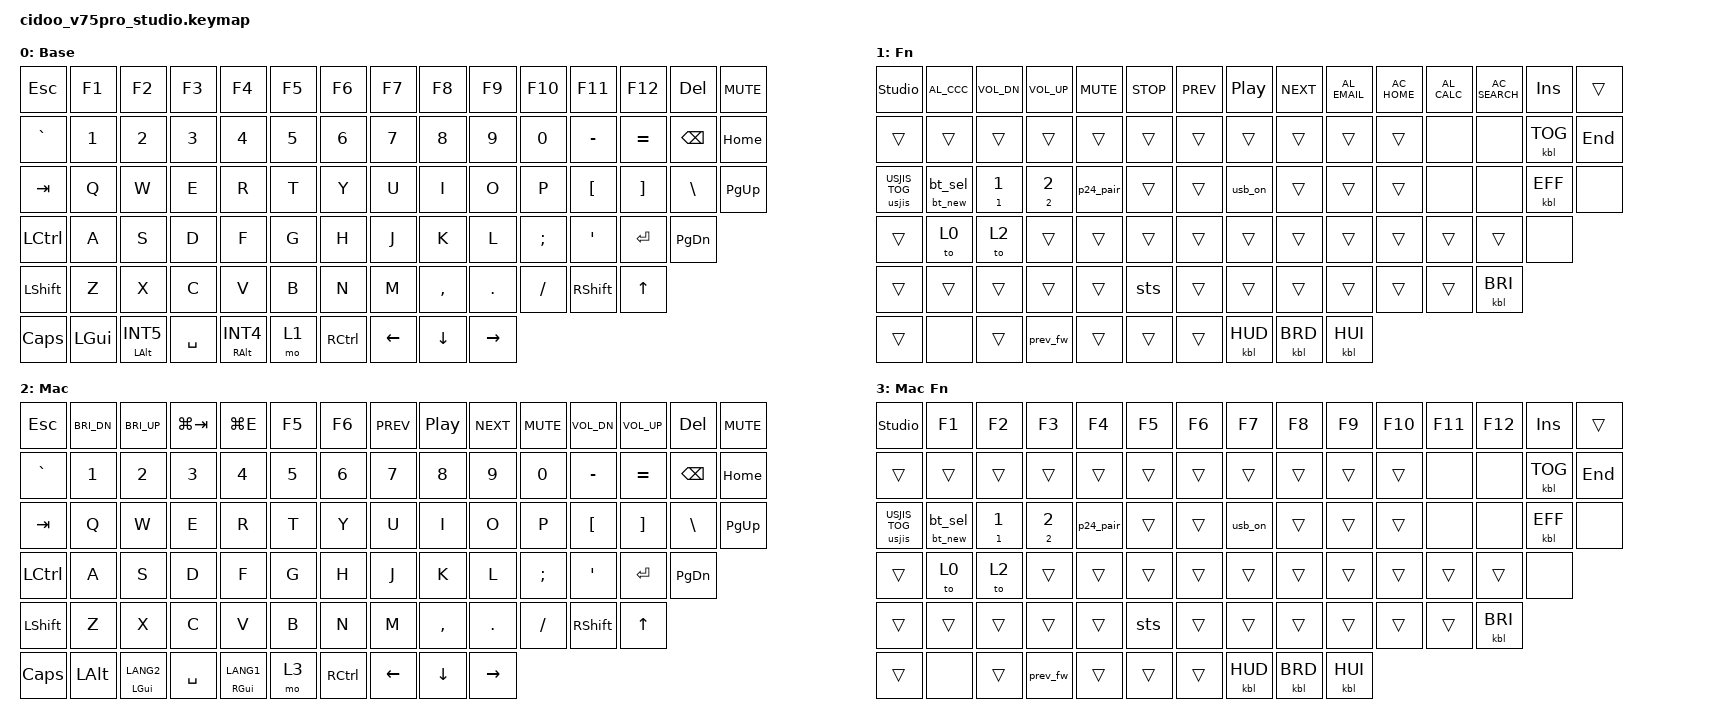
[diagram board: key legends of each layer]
/*
 * SPDX-License-Identifier: GPL-3.0-or-later
 */

/*
 * CIDOO V75 Pro keymap for the own BLE stack (TLSR_BLE), the 2.4G link (TLSR_P24),
 * the backlight (LED_DRIVER_SPI) and ZMK Studio over a USB serial port, with
 * the original firmware's Windows and Mac modes as layers: Base and Fn for Windows, Mac and Mac Fn
 * for the Mac. Fn + S (the original firmware's MAC MODE) turns the Mac layer on, Fn + A (WIN MODE)
 * off, and the layer's state is kept over a boot (TLSR_KEPT_LAYER). The Mac layers are
 * the original firmware's Mac mode as seen on it: F1/F2 the display brightness, F3/F4 Cmd+Tab and
 * Cmd+E, F7-F12 the media keys, Alt and Cmd swapped, the right Alt a Cmd; with Fn the F
 * row gives F1-F12. Fn + Esc unlocks Studio.
 * US-JIS (src/usjis.c): Fn + Tab toggles it (&usjis USJIS_TOG; Studio also offers On and
 * Off), only the Win layers substitute (CONFIG_ZMK_USJIS_LAYER_EXCLUDE_MASK), and a change
 * blinks the LEDs left of the knob green (on) or red (off). Defaults any key can be given
 * back in Studio: Caps Lock and the left Ctrl swapped, and the keys beside Space hold their
 * modifier and tap the IME keys (&ime_ht, hold-preferred, 200 ms): Win Alt / Muhenkan
 * (INT5) and Alt / Henkan (INT4), Mac Cmd / Eisu (LANG2) and Cmd / Kana (LANG1).
 * The backlight keymap is cidoo_v75pro_wireless.keymap: cidoo_v75pro_ble.keymap with the
 * original firmware's backlight keys bound (&kbl): Fn + Backspace toggles, Fn + \ steps the
 * effect, Fn + Up/Down the brightness, Fn + Right/Left the colour, as on the
 * original firmware. The original firmware's speed and saturation keys stay unbound.
 * The BLE keymap is the same as cidoo_v75pro.keymap but for the original firmware's BT channel keys
 * (Fn + Q/W/E): a tap selects ZMK profile 0/1/2, held 3 s it selects it and clears
 * its bond; and the original firmware's 2.4G key (Fn + R): held 3 s in the 2.4G position, it pairs.
 * Generated by gen_v75pro.py from the original keymap's layers 0 (Base) and 1 (Fn).
 * Original knob: left = &kp C_VOL_DN, right = &kp C_VOL_UP, press = 0,14.
 */

#include <behaviors.dtsi>
#include <dt-bindings/zmk/keys.h>
#include <dt-bindings/zmk/bt.h>
#include <dt-bindings/zmk/rgb.h>
#include <dt-bindings/zmk/usjis.h>

/ {
    chosen {
        zmk,studio-rpc-uart = &studio_rpc_usb_uart;
    };
};

/ {
    macros {
        bt_sel: bt_sel {
            compatible = "zmk,behavior-macro-one-param";
            #binding-cells = <1>;
            bindings = <&macro_param_1to2>, <&bt BT_SEL MACRO_PLACEHOLDER>;
        };
        bt_new: bt_new {
            compatible = "zmk,behavior-macro-one-param";
            #binding-cells = <1>;
            bindings = <&macro_param_1to2>, <&bt BT_SEL MACRO_PLACEHOLDER>, <&bt BT_CLR>;
        };
    };

    behaviors {
        /* The original firmware's 2.4G pairing key, Fn + R held 3 s (the 2.4G position only) */
        /* ZMK's RGB commands for the backlight (src/led_driver_spi.c) */
        kbl: backlight {
            compatible = "zmk,behavior-backlight-rgb";
            #binding-cells = <2>;
        };
        p24_pair: p24_pair {
            compatible = "zmk,behavior-p24-pair";
            #binding-cells = <0>;
            hold-ms = <3000>;
        };
        usjis: usjis {
            compatible = "zmk,behavior-usjis";
            #binding-cells = <1>;
            display-name = "US-JIS";
        };
        /* Modifier when held, IME key when tapped (the keys beside Space). hold-preferred:
         * a key pressed while it is held makes it the modifier, so shortcuts are not delayed. */
        ime_ht: ime_ht {
            compatible = "zmk,behavior-hold-tap";
            #binding-cells = <2>;
            display-name = "IME Hold-Tap";
            flavor = "hold-preferred";
            tapping-term-ms = <200>;
            bindings = <&kp>, <&kp>;
        };
        /* the status display (src/status_display.c): the battery, the CPU left, the links */
        sts: status {
            compatible = "zmk,behavior-status-display";
            #binding-cells = <0>;
        };
        /* USB in the BT and 2.4G positions until the power goes, for the host tools (no keys over it) */
        usb_on: usb_request {
            compatible = "zmk,behavior-usb-request";
            #binding-cells = <0>;
            display-name = "USB on (BT, 2.4G)";
        };
        bt_ch: bt_ch {
            compatible = "zmk,behavior-hold-tap";
            #binding-cells = <2>;
            flavor = "tap-preferred";
            tapping-term-ms = <3000>;
            bindings = <&bt_new>, <&bt_sel>;
        };
    };

    keymap {
        compatible = "zmk,keymap";

        base_layer {
            display-name = "Base";
            bindings = <
                &kp ESC         &kp F1          &kp F2          &kp F3          &kp F4          &kp F5          &kp F6          &kp F7          &kp F8          &kp F9          &kp F10         &kp F11         &kp F12         &kp DEL         &kp C_MUTE
                &kp GRAVE       &kp N1          &kp N2          &kp N3          &kp N4          &kp N5          &kp N6          &kp N7          &kp N8          &kp N9          &kp N0          &kp MINUS       &kp EQUAL       &kp BSPC        &kp HOME
                &kp TAB         &kp Q           &kp W           &kp E           &kp R           &kp T           &kp Y           &kp U           &kp I           &kp O           &kp P           &kp LBKT        &kp RBKT        &kp BSLH        &kp PG_UP
                &kp LCTRL       &kp A           &kp S           &kp D           &kp F           &kp G           &kp H           &kp J           &kp K           &kp L           &kp SEMI        &kp SQT         &kp RET         &kp PG_DN
                &kp LSHFT       &kp Z           &kp X           &kp C           &kp V           &kp B           &kp N           &kp M           &kp COMMA       &kp DOT         &kp FSLH        &kp RSHFT       &kp UP
                &kp CAPS        &kp LGUI        &ime_ht LALT INT5 &kp SPACE     &ime_ht RALT INT4 &mo 1           &kp RCTRL       &kp LEFT        &kp DOWN        &kp RIGHT
            >;
            sensor-bindings = <&inc_dec_kp C_VOL_UP C_VOL_DN>;
        };

        fn_layer {
            /* Original bindings left out (matrix row,col):
             *   1,11: RGB_SPD (not bound)
             *   1,12: RGB_SPI (not bound)
             *   2,11: RGB_SAI (not bound)
             *   2,12: RGB_SAD (not bound)
             *   2,14: LED LOGO MODE (original firmware only)
             *   3,14: LED LOGO COLOUR (original firmware only)
             *   4,6: BATT ST (original firmware only)
             *   5,1: LOCK WIN KEY (original firmware only)
             */
            display-name = "Fn";
            bindings = <
                &studio_unlock  &kp C_AL_CCC    &kp C_VOL_DN    &kp C_VOL_UP    &kp C_MUTE      &kp C_STOP      &kp C_PREV      &kp C_PP        &kp C_NEXT      &kp C_AL_EMAIL  &kp C_AC_HOME   &kp C_AL_CALC   &kp C_AC_SEARCH &kp INS         &trans
                &trans          &trans          &trans          &trans          &trans          &trans          &trans          &trans          &trans          &trans          &trans          &none           &none           &kbl RGB_TOG    &kp END
                &usjis USJIS_TOG &bt_ch 0 0     &bt_ch 1 1      &bt_ch 2 2      &p24_pair       &trans          &trans          &usb_on         &trans          &trans          &trans          &none           &none           &kbl RGB_EFF    &none
                &trans          &to 0           &to 2           &trans          &trans          &trans          &trans          &trans          &trans          &trans          &trans          &trans          &trans          &none
                &trans          &trans          &trans          &trans          &trans          &sts            &trans          &trans          &trans          &trans          &trans          &trans          &kbl RGB_BRI
                &trans          &none           &trans          &prev_fw        &trans          &trans          &trans          &kbl RGB_HUD    &kbl RGB_BRD    &kbl RGB_HUI
            >;
            sensor-bindings = <&inc_dec_kp C_VOL_UP C_VOL_DN>;
        };

        mac_layer {
            /* The original firmware's Mac mode: Base with the F row and the modifiers changed; Fn holds Mac Fn */
            display-name = "Mac";
            bindings = <
                &kp ESC         &kp C_BRI_DN    &kp C_BRI_UP    &kp LG(TAB)     &kp LG(E)       &kp F5          &kp F6          &kp C_PREV      &kp C_PP        &kp C_NEXT      &kp C_MUTE      &kp C_VOL_DN    &kp C_VOL_UP    &kp DEL         &kp C_MUTE
                &kp GRAVE       &kp N1          &kp N2          &kp N3          &kp N4          &kp N5          &kp N6          &kp N7          &kp N8          &kp N9          &kp N0          &kp MINUS       &kp EQUAL       &kp BSPC        &kp HOME
                &kp TAB         &kp Q           &kp W           &kp E           &kp R           &kp T           &kp Y           &kp U           &kp I           &kp O           &kp P           &kp LBKT        &kp RBKT        &kp BSLH        &kp PG_UP
                &kp LCTRL       &kp A           &kp S           &kp D           &kp F           &kp G           &kp H           &kp J           &kp K           &kp L           &kp SEMI        &kp SQT         &kp RET         &kp PG_DN
                &kp LSHFT       &kp Z           &kp X           &kp C           &kp V           &kp B           &kp N           &kp M           &kp COMMA       &kp DOT         &kp FSLH        &kp RSHFT       &kp UP
                &kp CAPS        &kp LALT        &ime_ht LGUI LANG2 &kp SPACE    &ime_ht RGUI LANG1 &mo 3           &kp RCTRL       &kp LEFT        &kp DOWN        &kp RIGHT
            >;
            sensor-bindings = <&inc_dec_kp C_VOL_UP C_VOL_DN>;
        };

        mac_fn_layer {
            /* Fn with the F row as F1-F12 */
            display-name = "Mac Fn";
            bindings = <
                &studio_unlock  &kp F1          &kp F2          &kp F3          &kp F4          &kp F5          &kp F6          &kp F7          &kp F8          &kp F9          &kp F10         &kp F11         &kp F12         &kp INS         &trans
                &trans          &trans          &trans          &trans          &trans          &trans          &trans          &trans          &trans          &trans          &trans          &none           &none           &kbl RGB_TOG    &kp END
                &usjis USJIS_TOG &bt_ch 0 0     &bt_ch 1 1      &bt_ch 2 2      &p24_pair       &trans          &trans          &usb_on         &trans          &trans          &trans          &none           &none           &kbl RGB_EFF    &none
                &trans          &to 0           &to 2           &trans          &trans          &trans          &trans          &trans          &trans          &trans          &trans          &trans          &trans          &none
                &trans          &trans          &trans          &trans          &trans          &sts            &trans          &trans          &trans          &trans          &trans          &trans          &kbl RGB_BRI
                &trans          &none           &trans          &prev_fw        &trans          &trans          &trans          &kbl RGB_HUD    &kbl RGB_BRD    &kbl RGB_HUI
            >;
            sensor-bindings = <&inc_dec_kp C_VOL_UP C_VOL_DN>;
        };
    };
};

/* ZMK Studio's serial port */
&usbd {
    studio_rpc_usb_uart: studio_rpc_usb_uart {
        compatible = "zephyr,cdc-acm-uart";
    };
};

/* Not on these keyboards: &sys_reset only reboots (settings stay), and &bootloader has no
 * bootloader to enter (firmware updates go through the update tool). */
&sys_reset {
	status = "disabled";
};

&bootloader {
	status = "disabled";
};
